# RE01_1500KB register map
Vendor: Renesas Electronics Corporation; Series: RE01_1500KB; File version: 1.20
CPU: CM0PLUS r0p1, little endian, MPU, no FPU, VTOR, 2 interrupt priority bits
Registers are 8-bit, read-write, reset 0x0 unless marked. A register's access mark holds for its fields unless they carry their own. Offsets are from the block's base; [hi:lo] are bit positions; {n}, {i} and the like mark numbered series; 'fields as' and 'values as' point back to an identical list.

## PFS — Pmn Pin Function Control Register
Base 0x40040800
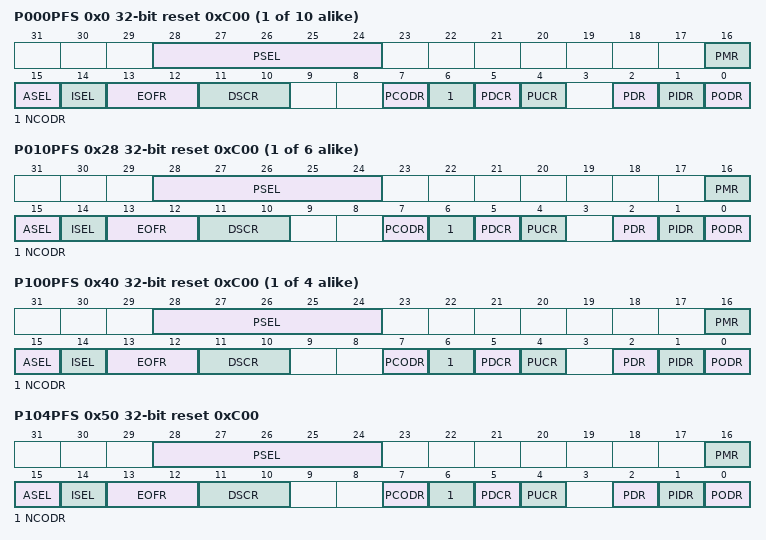
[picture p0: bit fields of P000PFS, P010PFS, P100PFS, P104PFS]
{0x0+4i} P00{i}PFS (i=0..9) 32-bit reset 0xC00 (reset mask 0xFFFFFFFD) — P00{i} Pin Function Control Register
  [28:24] PSEL — Port Function SelectThese bits select the peripheral function. For individual pin functions, see the MPC table
  [16] PMR — Port Mode Control
    0=Uses the pin as a general I/O pin; 1=Uses the pin as an I/O port for peripheral functions
  [15] ASEL — Analog Input enable
    0=Used other than as analog pin; 1=Used as analog pin
  [14] ISEL — IRQ input enable
    0=Not used as IRQn input pin; 1=Used as IRQn input pin
  [13:12] EOFR
    0=00; 1=01; 2=10; 3=11
  [11:10] DSCR — Drive Strength Control Register
    0=00; 1=01; 2=10; 3=11
  [7] PCODR
  [6] NCODR — N-Channel Open Drain Control
    0=CMOS output; 1=NMOS open-drain output
  [5] PDCR
  [4] PUCR — Pull-up Control
    0=Disables an input pull-up; 1=Enables an input pull-up
  [2] PDR — Port Direction
    0=Input (Functions as an input pin.); 1=Output (Functions as an output pin.)
  [1] PIDR ro — Port Input Data
    0=Low input; 1=High input
  [0] PODR — Port Output Data
    0=Low output; 1=High output
{0x0+4i} P0{i}PFS (i=10..15) 32-bit reset 0xC00 (reset mask 0xFFFFFFFD) — P0{i} Pin Function Control Register
  fields as P000PFS
{0x40+4i} P10{i}PFS (i=0..3) 32-bit reset 0xC00 (reset mask 0xFFFFFFFD) — P10{i} Pin Function Control Register
  fields as P000PFS
0x50 P104PFS 32-bit reset 0xC00 (reset mask 0xFFFFFFFD) — P104 Pin Function Control Register
  [28:24] PSEL — Port Function SelectThese bits select the peripheral function. For individual pin functions, see the MPC table
  [16] PMR — Port Mode Control
    values as P000PFS.PMR
  [15] ASEL — Analog Input enable
    0=Used other than as analog pin; 1=Used as analog pin
  [14] ISEL — IRQ input enable
    0=Not used as IRQn input pin; 1=Used as IRQn input pin
  [13:12] EOFR
    0=00; 1=01; 2=10; 3=11
  [11:10] DSCR — Drive Strength Control Register
    0=00; 1=01; 2=10; 3=11
  [7] PCODR
  [6] NCODR — N-Channel Open Drain Control
    0=CMOS output; 1=NMOS open-drain output
  [5] PDCR — This bit is read as 0. The write value should be 0.
  [4] PUCR — Pull-up Control
    0=Disables an input pull-up; 1=Enables an input pull-up
  [2] PDR — Port Direction
    values as P000PFS.PDR
  [1] PIDR ro — Port Input Data
    0=Low input; 1=High input
  [0] PODR — Port Output Data
    0=Low output; 1=High output
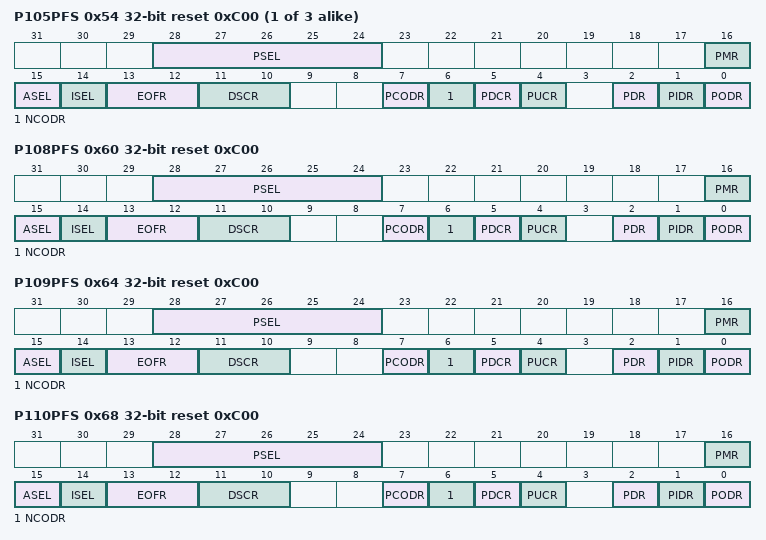
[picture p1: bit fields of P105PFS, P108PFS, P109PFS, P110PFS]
{0x40+4i} P10{i}PFS (i=5..7) 32-bit reset 0xC00 (reset mask 0xFFFFFFFD) — P10{i} Pin Function Control Register
  fields as P104PFS
0x60 P108PFS 32-bit reset 0xC00 (reset mask 0xFFFFFFFD) — P0108 Pin Function Control Register
  fields as P104PFS
0x64 P109PFS 32-bit reset 0xC00 (reset mask 0xFFFFFFFD) — P109 Pin Function Control Register
  fields as P104PFS
0x68 P110PFS 32-bit reset 0xC00 (reset mask 0xFFFFFFFD) — P110 Pin Function Control Register
  fields as P104PFS
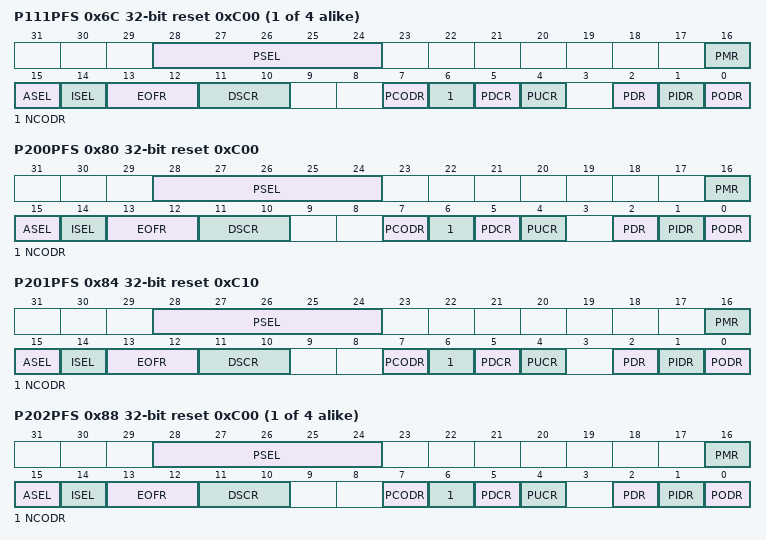
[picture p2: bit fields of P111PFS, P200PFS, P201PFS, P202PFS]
{0x40+4i} P1{i}PFS (i=11..14) 32-bit reset 0xC00 (reset mask 0xFFFFFFFD) — P1{i} Pin Function Control Register
  fields as P000PFS
0x80 P200PFS 32-bit reset 0xC00 (reset mask 0xFFFFFFFD) — P200 Pin Function Control Register
  fields as P000PFS
0x84 P201PFS 32-bit reset 0xC10 (reset mask 0xFFFFFFFD) — P201 Pin Function Control Register
  fields as P000PFS
{0x80+4i} P20{i}PFS (i=2..5) 32-bit reset 0xC00 (reset mask 0xFFFFFFFD) — P20{i} Pin Function Control Register
  fields as P000PFS
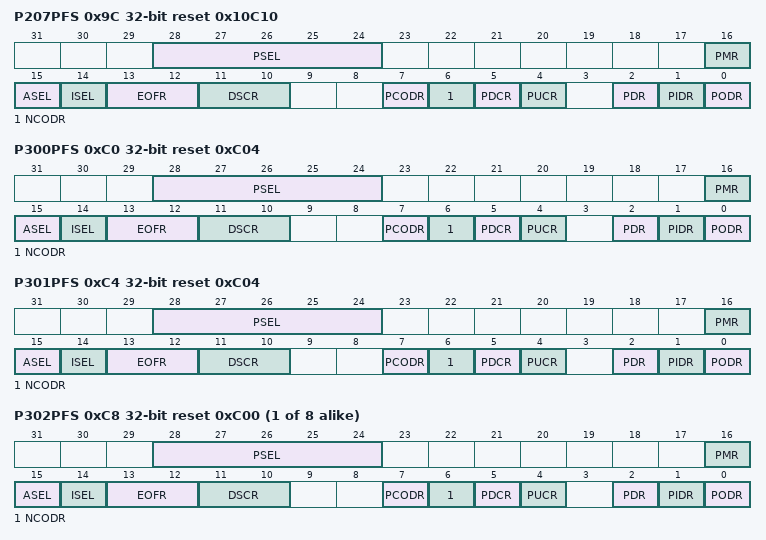
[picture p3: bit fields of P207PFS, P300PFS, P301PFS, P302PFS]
0x9C P207PFS 32-bit reset 0x10C10 (reset mask 0xFFFFFFFD) — P207 Pin Function Control Register
  fields as P104PFS
0xC0 P300PFS 32-bit reset 0xC04 (reset mask 0xFFFFFFFD) — P300 Pin Function Control Register
  fields as P000PFS
0xC4 P301PFS 32-bit reset 0xC04 (reset mask 0xFFFFFFFD) — P301 Pin Function Control Register
  fields as P000PFS
{0xC0+4i} P30{i}PFS (i=2..9) 32-bit reset 0xC00 (reset mask 0xFFFFFFFD) — P30{i} Pin Function Control Register
  fields as P000PFS
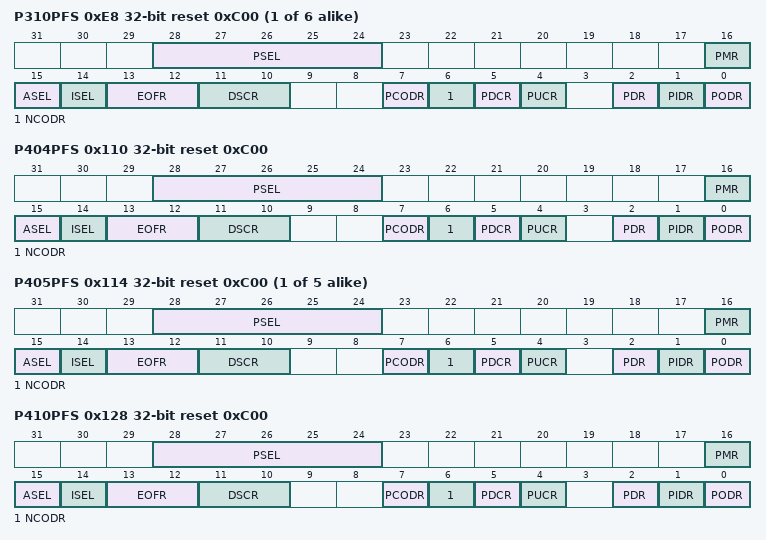
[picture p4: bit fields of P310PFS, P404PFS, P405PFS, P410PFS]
{0xC0+4i} P3{i}PFS (i=10..15) 32-bit reset 0xC00 (reset mask 0xFFFFFFFD) — P3{i} Pin Function Control Register
  fields as P000PFS
0x110 P404PFS 32-bit reset 0xC00 (reset mask 0xFFFFFFFD) — P404 Pin Function Control Register
  fields as P000PFS
{0x100+4i} P40{i}PFS (i=5..9) 32-bit reset 0xC00 (reset mask 0xFFFFFFFD) — P40{i} Pin Function Control Register
  fields as P000PFS
0x128 P410PFS 32-bit reset 0xC00 (reset mask 0xFFFFFFFD) — P410 Pin Function Control Register
  fields as P000PFS
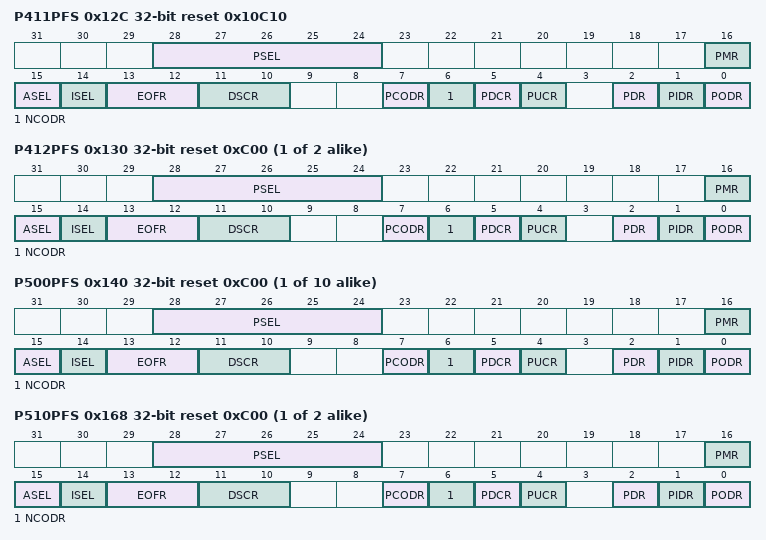
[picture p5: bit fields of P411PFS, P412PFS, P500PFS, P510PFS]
0x12C P411PFS 32-bit reset 0x10C10 (reset mask 0xFFFFFFFD) — P411 Pin Function Control Register
  fields as P000PFS
{0x100+4i} P4{i}PFS (i=12..13) 32-bit reset 0xC00 (reset mask 0xFFFFFFFD) — P4{i} Pin Function Control Register
  fields as P000PFS
{0x140+4i} P50{i}PFS (i=0..9) 32-bit reset 0xC00 (reset mask 0xFFFFFFFD) — P50{i} Pin Function Control Register
  fields as P000PFS
{0x140+4i} P5{i}PFS (i=10..11) 32-bit reset 0xC00 (reset mask 0xFFFFFFFD) — P5{i} Pin Function Control Register
  fields as P000PFS
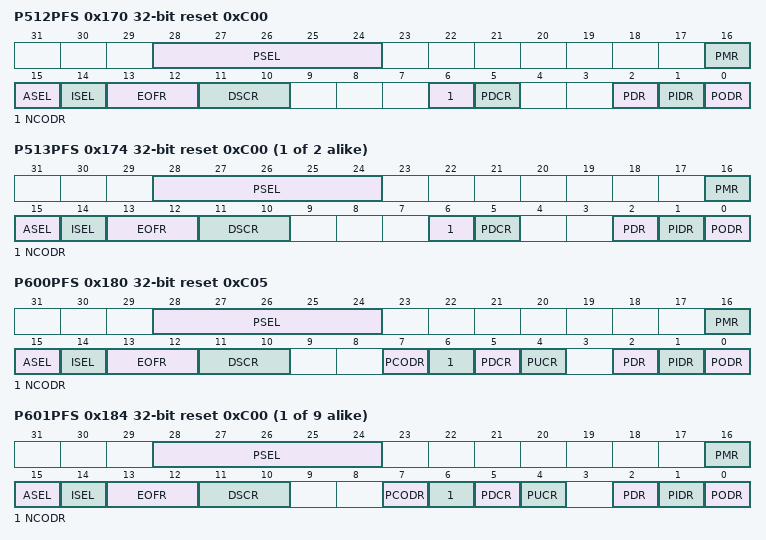
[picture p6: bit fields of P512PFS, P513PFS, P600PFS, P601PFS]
0x170 P512PFS 32-bit reset 0xC00 (reset mask 0xFFFFFFFD) — P512 Pin Function Control Register
  [28:24] PSEL — Port Function SelectThese bits select the peripheral function. For individual pin functions, see the MPC table
  [16] PMR — Port Mode Control
    values as P000PFS.PMR
  [15] ASEL — Analog Input enable
    0=Used other than as analog pin; 1=Used as analog pin
  [14] ISEL — IRQ input enable
    0=Not used as IRQn input pin; 1=Used as IRQn input pin
  [13:12] EOFR
    0=00; 1=01; 2=10; 3=11
  [11:10] DSCR — Drive Strength Control Register
    0=00; 1=01; 2=10; 3=11
  [6] NCODR — N-Channel Open Drain Control
    0=CMOS output; 1=NMOS open-drain output
  [5] PDCR
  [2] PDR — Port Direction
    values as P000PFS.PDR
  [1] PIDR ro — Port Input Data
    0=Low input; 1=High input
  [0] PODR — Port Output Data
    0=Low output; 1=High output
{0x140+4i} P5{i}PFS (i=13..14) 32-bit reset 0xC00 (reset mask 0xFFFFFFFD) — P5{i} Pin Function Control Register
  fields as P512PFS
0x180 P600PFS 32-bit reset 0xC05 (reset mask 0xFFFFFFFD) — P600 Pin Function Control Register
  fields as P000PFS
{0x180+4i} P60{i}PFS (i=1..9) 32-bit reset 0xC00 (reset mask 0xFFFFFFFD) — P60{i} Pin Function Control Register
  fields as P000PFS
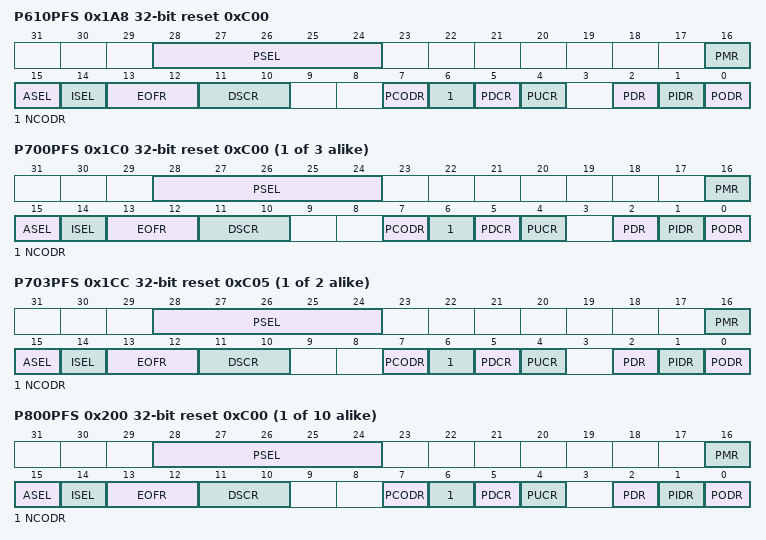
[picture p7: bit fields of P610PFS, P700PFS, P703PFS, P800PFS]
0x1A8 P610PFS 32-bit reset 0xC00 (reset mask 0xFFFFFFFD) — P610 Pin Function Control Register
  fields as P000PFS
{0x1C0+4i} P70{i}PFS (i=0..2) 32-bit reset 0xC00 (reset mask 0xFFFFFFFD) — P70{i} Pin Function Control Register
  fields as P000PFS
{0x1C0+4i} P70{i}PFS (i=3..4) 32-bit reset 0xC05 (reset mask 0xFFFFFFFD) — P70{i} Pin Function Control Register
  fields as P000PFS
{0x200+4i} P80{i}PFS (i=0..9) 32-bit reset 0xC00 (reset mask 0xFFFFFFFD) — P80{i} Pin Function Control Register
  fields as P000PFS
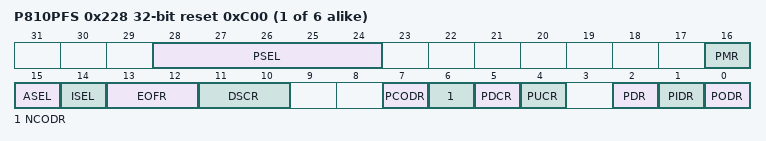
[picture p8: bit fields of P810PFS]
{0x200+4i} P8{i}PFS (i=10..15) 32-bit reset 0xC00 (reset mask 0xFFFFFFFD) — P8{i} Pin Function Control Register
  fields as P000PFS
